# R7FA2E307 register map
Vendor: Renesas Electronics Corporation; Series: RA2; File version: 1.20.00
CPU: CM23 r1p0, little endian, MPU, no FPU, VTOR, 2 interrupt priority bits, 32 interrupts
Registers are 8-bit, read-write, reset 0x0 unless marked. A register's access mark holds for its fields unless they carry their own. Offsets are from the block's base; [hi:lo] are bit positions; {n}, {i} and the like mark numbered series.

## DTC — Data Transfer Controller
Base 0x40005400
0x00 DTCCR reset 0x8 — DTC Control Register
  [4] RRS — DTC Transfer Information Read Skip Enable
0x04 DTCVBR 32-bit — DTC Vector Base Register
0x0C DTCST — DTC Module Start Register
  [0] DTCST — DTC Module Start
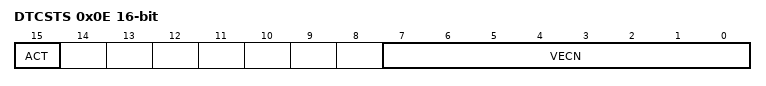
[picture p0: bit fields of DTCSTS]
0x0E DTCSTS 16-bit ro — DTC Status Register
  [15] ACT — DTC Active Flag
  [7:0] VECN — DTC,Activating Vector Number Monitoring

## DBG — Debug Function
Base 0x4001B000
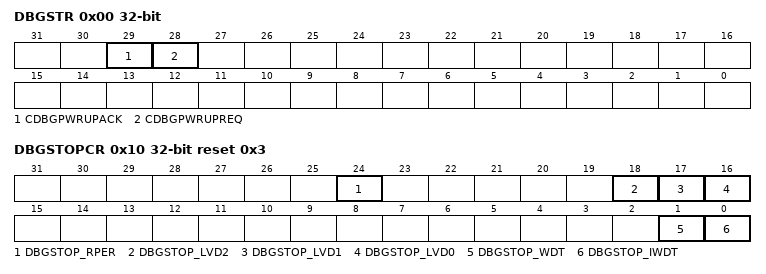
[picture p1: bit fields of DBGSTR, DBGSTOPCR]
0x00 DBGSTR 32-bit ro — Debug Status Register
  [29] CDBGPWRUPACK — Debug power,up acknowledge
  [28] CDBGPWRUPREQ — Debug power,up request
0x10 DBGSTOPCR 32-bit reset 0x3 — Debug Stop Control Register
  [24] DBGSTOP_RPER — Mask bit for SRAM parity error reset/interrupt
  [18] DBGSTOP_LVD2 — Mask bit for LVD2 reset/interrupt
  [17] DBGSTOP_LVD1 — Mask bit for LVD1 reset/interrupt
  [16] DBGSTOP_LVD0 — Mask bit for LVD0 reset
  [1] DBGSTOP_WDT — Mask bit for WDT reset/interrupt in the OCD run mode
  [0] DBGSTOP_IWDT — Mask bit for IWDT reset/interrupt in the OCD run mode

## PORT0 — Port 0 Control Registers
Base 0x40040000
Same registers: PORT3 0x40040060, PORT4 0x40040080, PORT5 0x400400A0, PORT9 0x40040120
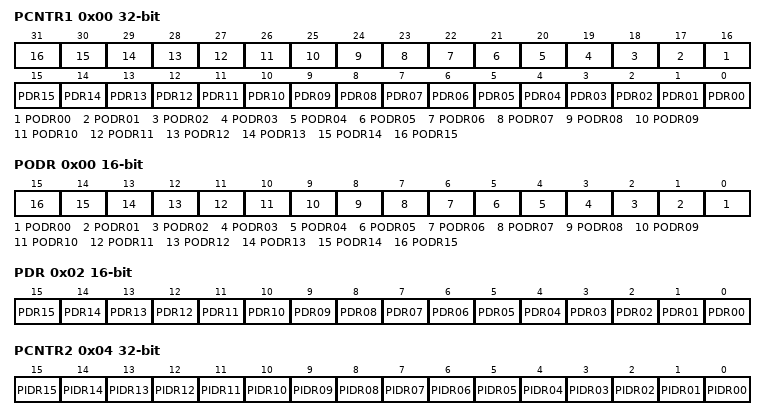
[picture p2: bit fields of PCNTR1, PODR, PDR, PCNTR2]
0x00 PCNTR1 32-bit — Port Control Register 1
  [n+16] PODR{n:02} (n=0..15) — Pmn Output Data
  [n] PDR{n:02} (n=0..15) — Pmn Direction
0x00 PODR 16-bit (alternate view of PCNTR1) — Port Control Register 1
  [n] PODR{n:02} (n=0..15) — Pmn Output Data
0x02 PDR 16-bit (alternate view of PCNTR1) — Port Control Register 1
  [n] PDR{n:02} (n=0..15) — Pmn Direction
0x04 PCNTR2 32-bit ro (reset mask 0xFFFF0000) — Port Control Register 2
  [n] PIDR{n:02} (n=0..15) — Pmn State
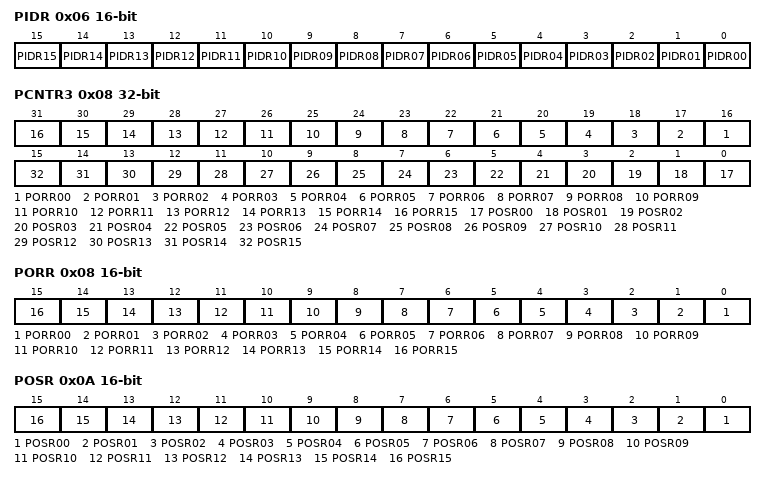
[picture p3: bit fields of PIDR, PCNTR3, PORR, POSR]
0x06 PIDR 16-bit ro reset not defined (alternate view of PCNTR2) — Port Control Register 2
  [n] PIDR{n:02} (n=0..15) — Pmn State
0x08 PCNTR3 32-bit wo — Port Control Register 3
  [n+16] PORR{n:02} (n=0..15) — Pmn Output Reset
  [n] POSR{n:02} (n=0..15) — Pmn Output Set
0x08 PORR 16-bit wo (alternate view of PCNTR3) — Port Control Register 3
  [n] PORR{n:02} (n=0..15) — Pmn Output Reset
0x0A POSR 16-bit wo (alternate view of PCNTR3) — Port Control Register 3
  [n] POSR{n:02} (n=0..15) — Pmn Output Set

## PORT1 — Port 1 Control Registers
Base 0x40040020
Same registers: PORT2 0x40040040
Registers as PORT0; these are added or differ:
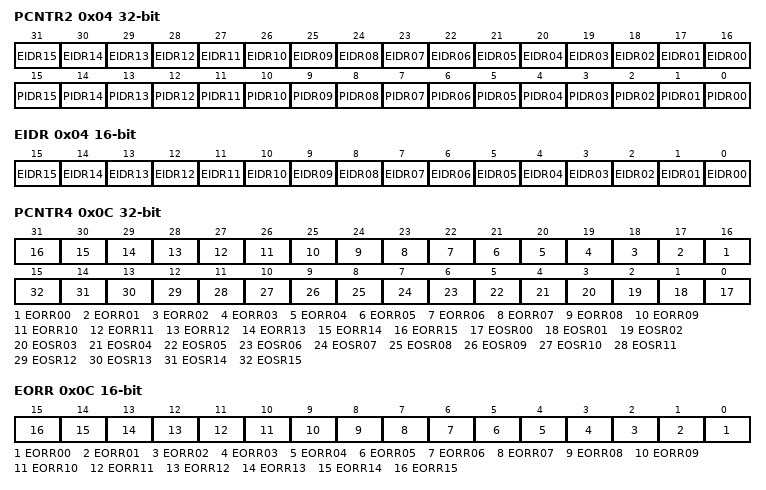
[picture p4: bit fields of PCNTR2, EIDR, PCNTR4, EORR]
0x04 PCNTR2 32-bit ro (reset mask 0xFFFF0000) — Port Control Register 2
  [n+16] EIDR{n:02} (n=0..15) — Port Event Input Data
  [n] PIDR{n:02} (n=0..15) — Pmn State
0x04 EIDR 16-bit ro (alternate view of PCNTR2) — Port Control Register 2
  [n] EIDR{n:02} (n=0..15) — Port Event Input Data
0x0C PCNTR4 32-bit — Port Control Register 4
  [n+16] EORR{n:02} (n=0..15) — Pmn Event Output Reset
  [n] EOSR{n:02} (n=0..15) — Pmn Event Output Set
0x0C EORR 16-bit (alternate view of PCNTR4) — Port Control Register 4
  [n] EORR{n:02} (n=0..15) — Pmn Event Output Reset
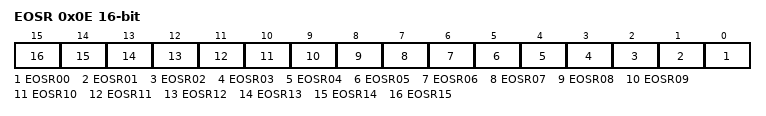
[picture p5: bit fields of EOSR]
0x0E EOSR 16-bit (alternate view of PCNTR4) — Port Control Register 4
  [n] EOSR{n:02} (n=0..15) — Pmn Event Output Set

## ELC — Event Link Controller
Base 0x40041000
0x00 ELCR — Event Link Controller Register
  [7] ELCON — All Event Link Enable
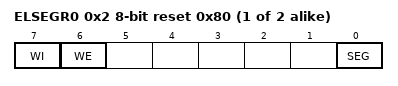
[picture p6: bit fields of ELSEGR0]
{0x2+2i} ELSEGR{i} (i=0..1) reset 0x80 — Event Link Software Event Generation Register {i}
  [7] WI wo — ELSEGR Register Write Disable
  [6] WE — SEG Bit Write Enable
  [0] SEG wo — Software Event Generation
{0x10+4i} ELSR{i} (i=0..3) 16-bit — Event Link Setting Register {i}
  [7:0] ELS — Event Link Select
{0x10+4i} ELSR{i}_1 (i=8..9) 16-bit — Event Link Setting Register {i}
  [7:0] ELS — Event Link Select
{0x10+4i} ELSR{i}_2 (i=14..15) 16-bit — Event Link Setting Register {i}
  [7:0] ELS — Event Link Select
